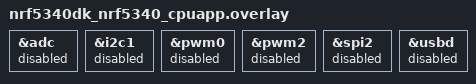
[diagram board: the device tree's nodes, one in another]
/* Disable unused peripherals to reduce power consumption */
&adc {
	status = "disabled";
};
&i2c1 {
	status = "disabled";
};
&pwm0 {
	status = "disabled";
};
&pwm2 {
	status = "disabled";
};
&spi2 {
	status = "disabled";
};
&usbd {
	status = "disabled";
};
